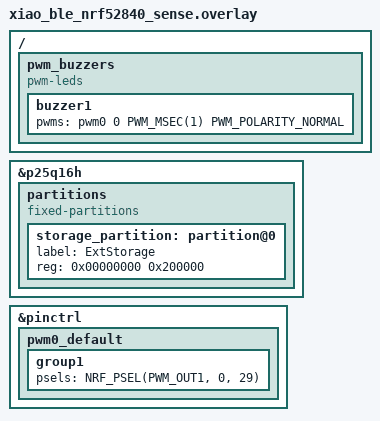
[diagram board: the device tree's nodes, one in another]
/*
 * Copyright (c) 2025 Ned Konz <ned@metamagix.tech>
 *
 * SPDX-License-Identifier: Apache-2.0
 */

 // Replace default on-chip flash with external flash
/delete-node/ &storage_partition;

// 16Mib (2MiB) flash, mount as /flash
&p25q16h {
	partitions {
		compatible = "fixed-partitions";
		#address-cells = <1>;
		#size-cells = <1>;

		storage_partition: partition@0 {
			label = "ExtStorage";
			reg = <0x00000000 0x200000>;
		};
	};
};


/ {
    pwm_buzzers {
        compatible = "pwm-leds";
        buzzer1: buzzer1 {
            pwms = <&pwm0 0 PWM_MSEC(1) PWM_POLARITY_NORMAL>;
        };
    };
};

&pinctrl {
    pwm0_default: pwm0_default {
        group1 {
            // P0.29 has buzzer on XIAO extension board
            psels = <NRF_PSEL(PWM_OUT1, 0, 29)>;
        };
    };
};
